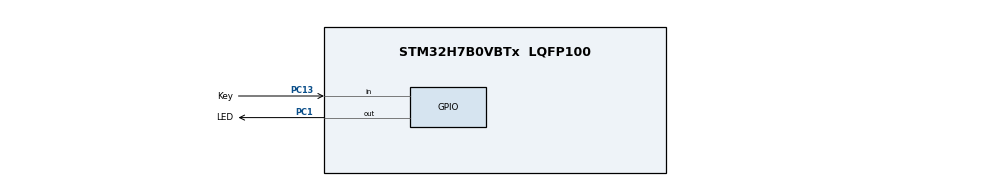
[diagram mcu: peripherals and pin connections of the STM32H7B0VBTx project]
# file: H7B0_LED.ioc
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Mcu.Family=STM32H7
Mcu.Name=STM32H7B0VBTx
Mcu.Package=LQFP100
NVIC.PriorityGroup=NVIC_PRIORITYGROUP_4
PC1.GPIO_Label=LED
PC1.GPIO_Speed=GPIO_SPEED_FREQ_HIGH
PC1.Signal=GPIO_Output
PC13.GPIO_Label=Key
PC13.GPIO_PuPd=GPIO_PULLUP
PC13.Signal=GPIO_Input
ProjectManager.HeapSize=0x200
ProjectManager.StackSize=0x400
ProjectManager.TargetToolchain=MDK-ARM V5.27
RCC.ADCFreq_Value=129000000
RCC.APB1Freq_Value=140000000
RCC.APB2Freq_Value=140000000
RCC.APB3Freq_Value=140000000
RCC.APB4Freq_Value=140000000
RCC.CDPPRE=RCC_APB3_DIV2
RCC.CDPPRE1=RCC_APB1_DIV2
RCC.CDPPRE2=RCC_APB2_DIV2
RCC.CortexFreq_Value=280000000
RCC.DIVM1=4
RCC.DIVN1=35
RCC.HCLKFreq_Value=280000000
RCC.PLL2FRACN=0
RCC.PLL3FRACN=0
RCC.PLLFRACN=0
RCC.SRDPPRE=RCC_APB4_DIV2
RCC.SYSCLKFreq_VALUE=280000000
RCC.SYSCLKSource=RCC_SYSCLKSOURCE_PLLCLK
RCC.USBFreq_Value=280000000
board=custom

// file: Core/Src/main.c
/* USER CODE BEGIN Header */
/**
  ******************************************************************************
  * @file           : main.c
  * @brief          : Main program body
  ******************************************************************************
  * @attention
  *
  * <h2><center>&copy; Copyright (c) 2022 STMicroelectronics.
  * All rights reserved.</center></h2>
  *
  * This software component is licensed by ST under BSD 3-Clause license,
  * the "License"; You may not use this file except in compliance with the
  * License. You may obtain a copy of the License at:
  *                        opensource.org/licenses/BSD-3-Clause
  *
  ******************************************************************************
  */
/* USER CODE END Header */
#include "main.h"

void SystemClock_Config(void);
static void MX_GPIO_Init(void);

int main(void)
{
  /* USER CODE BEGIN 1 */
    int a=0;
  /* USER CODE END 1 */

  /* MCU Configuration--------------------------------------------------------*/

  /* Reset of all peripherals, Initializes the Flash interface and the Systick. */
  HAL_Init();

  /* Configure the system clock */
  SystemClock_Config();

  /* Initialize all configured peripherals */
  MX_GPIO_Init();

  /* Infinite loop */
  while (1)
  {

    /* USER CODE BEGIN 3 */
      if(HAL_GPIO_ReadPin(Key_GPIO_Port,Key_Pin)==RESET)
      {
          HAL_Delay(10);
          if(HAL_GPIO_ReadPin(Key_GPIO_Port,Key_Pin)==RESET)
          {
              while(HAL_GPIO_ReadPin(Key_GPIO_Port,Key_Pin)==RESET);
              HAL_GPIO_TogglePin(LED_GPIO_Port,LED_Pin);
          }
      }
  }
  /* USER CODE END 3 */
}

void SystemClock_Config(void)
{
  RCC_OscInitTypeDef RCC_OscInitStruct = {0};
  RCC_ClkInitTypeDef RCC_ClkInitStruct = {0};

  /** Supply configuration update enable
  */
  HAL_PWREx_ConfigSupply(PWR_LDO_SUPPLY);
  /** Configure the main internal regulator output voltage
  */
  __HAL_PWR_VOLTAGESCALING_CONFIG(PWR_REGULATOR_VOLTAGE_SCALE0);

  while(!__HAL_PWR_GET_FLAG(PWR_FLAG_VOSRDY)) {}
  /** Initializes the RCC Oscillators according to the specified parameters
  * in the RCC_OscInitTypeDef structure.
  */
  RCC_OscInitStruct.OscillatorType = RCC_OSCILLATORTYPE_HSI;
  RCC_OscInitStruct.HSIState = RCC_HSI_DIV1;
  RCC_OscInitStruct.HSICalibrationValue = RCC_HSICALIBRATION_DEFAULT;
  RCC_OscInitStruct.PLL.PLLState = RCC_PLL_ON;
  RCC_OscInitStruct.PLL.PLLSource = RCC_PLLSOURCE_HSI;
  RCC_OscInitStruct.PLL.PLLM = 4;
  RCC_OscInitStruct.PLL.PLLN = 35;
  RCC_OscInitStruct.PLL.PLLP = 2;
  RCC_OscInitStruct.PLL.PLLQ = 2;
  RCC_OscInitStruct.PLL.PLLR = 2;
  RCC_OscInitStruct.PLL.PLLRGE = RCC_PLL1VCIRANGE_3;
  RCC_OscInitStruct.PLL.PLLVCOSEL = RCC_PLL1VCOWIDE;
  RCC_OscInitStruct.PLL.PLLFRACN = 0;
  if (HAL_RCC_OscConfig(&RCC_OscInitStruct) != HAL_OK)
  {
    Error_Handler();
  }
  /** Initializes the CPU, AHB and APB buses clocks
  */
  RCC_ClkInitStruct.ClockType = RCC_CLOCKTYPE_HCLK|RCC_CLOCKTYPE_SYSCLK
                              |RCC_CLOCKTYPE_PCLK1|RCC_CLOCKTYPE_PCLK2
                              |RCC_CLOCKTYPE_D3PCLK1|RCC_CLOCKTYPE_D1PCLK1;
  RCC_ClkInitStruct.SYSCLKSource = RCC_SYSCLKSOURCE_PLLCLK;
  RCC_ClkInitStruct.SYSCLKDivider = RCC_SYSCLK_DIV1;
  RCC_ClkInitStruct.AHBCLKDivider = RCC_HCLK_DIV1;
  RCC_ClkInitStruct.APB3CLKDivider = RCC_APB3_DIV2;
  RCC_ClkInitStruct.APB1CLKDivider = RCC_APB1_DIV2;
  RCC_ClkInitStruct.APB2CLKDivider = RCC_APB2_DIV2;
  RCC_ClkInitStruct.APB4CLKDivider = RCC_APB4_DIV2;

  if (HAL_RCC_ClockConfig(&RCC_ClkInitStruct, FLASH_LATENCY_7) != HAL_OK)
  {
    Error_Handler();
  }
}

static void MX_GPIO_Init(void)
{
  GPIO_InitTypeDef GPIO_InitStruct = {0};

  /* GPIO Ports Clock Enable */
  __HAL_RCC_GPIOC_CLK_ENABLE();

  /*Configure GPIO pin Output Level */
  HAL_GPIO_WritePin(LED_GPIO_Port, LED_Pin, GPIO_PIN_RESET);

  /*Configure GPIO pin : Key_Pin */
  GPIO_InitStruct.Pin = Key_Pin;
  GPIO_InitStruct.Mode = GPIO_MODE_INPUT;
  GPIO_InitStruct.Pull = GPIO_PULLUP;
  HAL_GPIO_Init(Key_GPIO_Port, &GPIO_InitStruct);

  /*Configure GPIO pin : LED_Pin */
  GPIO_InitStruct.Pin = LED_Pin;
  GPIO_InitStruct.Mode = GPIO_MODE_OUTPUT_PP;
  GPIO_InitStruct.Pull = GPIO_NOPULL;
  GPIO_InitStruct.Speed = GPIO_SPEED_FREQ_HIGH;
  HAL_GPIO_Init(LED_GPIO_Port, &GPIO_InitStruct);

}

void Error_Handler(void)
{
  __disable_irq();
  while (1)
  {
  }
}

/************************ (C) COPYRIGHT STMicroelectronics *****END OF FILE****/
